LIN_description_file;
LIN_protocol_version = "2.1";
LIN_language_version = "2.1";
LIN_speed = 19.2 kbps;

Nodes {
  Master: EVSE_Master, 1 ms, 0 ms ;
  Slaves: VehicleAC_charger_slave, Cable_Slave ;
}

Signals {
  EvSelectedVersion: 8, 255, VehicleAC_charger_slave, EVSE_Master ;
  EvResponseError: 1, 0, VehicleAC_charger_slave, EVSE_Master ;
  EvStatusVer: 2, 0, VehicleAC_charger_slave, EVSE_Master ;
  EvStatusInit: 2, 0, VehicleAC_charger_slave, EVSE_Master ;
  EvStatusOp: 2, 0, VehicleAC_charger_slave, EVSE_Master ;
  EvAwake: 1, 1, VehicleAC_charger_slave, EVSE_Master ;
  EvVersionPageNumber: 8, 0, VehicleAC_charger_slave, EVSE_Master ;
  EvSupportedVersion1: 8, 2, VehicleAC_charger_slave, EVSE_Master ;
  EvSupportedVersion2: 8, 255, VehicleAC_charger_slave, EVSE_Master ;
  EvSupportedVersion3: 8, 255, VehicleAC_charger_slave, EVSE_Master ;
  EvSupportedVersion4: 8, 255, VehicleAC_charger_slave, EVSE_Master ;
  EvSupportedVersion5: 8, 255, VehicleAC_charger_slave, EVSE_Master ;
  EvRequestedCurrentL1: 8, 255, VehicleAC_charger_slave, EVSE_Master ;
  EvRequestedCurrentL2: 8, 255, VehicleAC_charger_slave, EVSE_Master ;
  EvRequestedCurrentL3: 8, 255, VehicleAC_charger_slave, EVSE_Master ;
  EvRequestedCurrentN: 8, 255, VehicleAC_charger_slave, EVSE_Master ;
  SeSelectedVersion: 8, 255, EVSE_Master, VehicleAC_charger_slave ;
  SeStatusVer: 2, 0, EVSE_Master, VehicleAC_charger_slave ;
  SeStatusInit: 2, 0, EVSE_Master, VehicleAC_charger_slave ;
  SeStatusOp: 2, 0, EVSE_Master, VehicleAC_charger_slave ;
  SeVersionPageNumber: 8, 0, EVSE_Master, VehicleAC_charger_slave ;
  SeSupportedVersion1: 8, 2, EVSE_Master, VehicleAC_charger_slave ;
  SeSupportedVersion2: 8, 255, EVSE_Master, VehicleAC_charger_slave ;
  SeSupportedVersion3: 8, 255, EVSE_Master, VehicleAC_charger_slave ;
  SeSupportedVersion4: 8, 255, EVSE_Master, VehicleAC_charger_slave ;
  SeSupportedVersion5: 8, 255, EVSE_Master, VehicleAC_charger_slave ;
  SeAvailableCurrentL1: 8, 255, EVSE_Master, VehicleAC_charger_slave ;
  SeAvailableCurrentL2: 8, 255, EVSE_Master, VehicleAC_charger_slave ;
  SeAvailableCurrentL3: 8, 255, EVSE_Master, VehicleAC_charger_slave ;
  SeAvailableCurrentN: 8, 255, EVSE_Master, VehicleAC_charger_slave ;
  EvPresentCurrentL1: 8, 255, VehicleAC_charger_slave, EVSE_Master ;
  EvPresentCurrentL2: 8, 255, VehicleAC_charger_slave, EVSE_Master ;
  EvPresentCurrentL3: 8, 255, VehicleAC_charger_slave, EVSE_Master ;
  EvPresentCurrentN: 8, 255, VehicleAC_charger_slave, EVSE_Master ;
  SeNomVoltageL1N: 16, 65535, EVSE_Master, VehicleAC_charger_slave ;
  SeNomVoltageLL: 16, 65535, EVSE_Master, VehicleAC_charger_slave ;
  SeFrequency: 8, 255, EVSE_Master, VehicleAC_charger_slave ;
  SeMaxCurrentL1: 8, 255, EVSE_Master, VehicleAC_charger_slave ;
  SeMaxCurrentL2: 8, 255, EVSE_Master, VehicleAC_charger_slave ;
  SeMaxCurrentL3: 8, 255, EVSE_Master, VehicleAC_charger_slave ;
  SeMaxCurrentN: 8, 255, EVSE_Master, VehicleAC_charger_slave ;
  EvMaxVoltageL1N: 16, 65535, VehicleAC_charger_slave, EVSE_Master ;
  EvMaxVoltageLL: 16, 65535, VehicleAC_charger_slave, EVSE_Master ;
  EvFrequencies: 8, 255, VehicleAC_charger_slave, EVSE_Master ;
  EvMinVoltageL1N: 16, 65535, VehicleAC_charger_slave, EVSE_Master ;
  EvMinVoltageLL: 16, 65535, VehicleAC_charger_slave, EVSE_Master ;
  EvMaxCurrentL1: 8, 255, VehicleAC_charger_slave, EVSE_Master ;
  EvMaxCurrentL2: 8, 255, VehicleAC_charger_slave, EVSE_Master ;
  EvMaxCurrentL3: 8, 255, VehicleAC_charger_slave, EVSE_Master ;
  EvMaxCurrentN: 8, 255, VehicleAC_charger_slave, EVSE_Master ;
  EvMinCurrentL1: 8, 255, VehicleAC_charger_slave, EVSE_Master ;
  EvMinCurrentL2: 8, 255, VehicleAC_charger_slave, EVSE_Master ;
  EvMinCurrentL3: 8, 255, VehicleAC_charger_slave, EVSE_Master ;
  EvInfoEntry1: 8, 255, VehicleAC_charger_slave, EVSE_Master ;
  EvInfoEntry2: 8, 255, VehicleAC_charger_slave, EVSE_Master ;
  EvInfoEntry3: 8, 255, VehicleAC_charger_slave, EVSE_Master ;
  EvInfoEntry4: 8, 255, VehicleAC_charger_slave, EVSE_Master ;
  EvInfoEntry5: 8, 255, VehicleAC_charger_slave, EVSE_Master ;
  EvInfoEntry6: 8, 255, VehicleAC_charger_slave, EVSE_Master ;
  SeInfoEntry1: 8, 255, EVSE_Master, VehicleAC_charger_slave ;
  SeInfoEntry2: 8, 255, EVSE_Master, VehicleAC_charger_slave ;
  SeInfoEntry3: 8, 255, EVSE_Master, VehicleAC_charger_slave ;
  SeInfoEntry4: 8, 255, EVSE_Master, VehicleAC_charger_slave ;
  SeInfoEntry5: 8, 255, EVSE_Master, VehicleAC_charger_slave ;
  SeInfoEntry6: 8, 255, EVSE_Master, VehicleAC_charger_slave ;
  EvInfoPageNumber: 8, 0, VehicleAC_charger_slave, EVSE_Master ;
  SeInfoPageNumber: 8, 0, EVSE_Master, VehicleAC_charger_slave ;
  CaVersion: 8, 0, Cable_Slave, EVSE_Master ;
  CaResponseError: 1, 0, Cable_Slave, EVSE_Master ;
  CaMaxVoltage: 16, 65535, Cable_Slave, EVSE_Master ;
  CaMaxCurrentL1: 8, 255, Cable_Slave, EVSE_Master ;
  CaMaxCurrentL2: 8, 255, Cable_Slave, EVSE_Master ;
  CaMaxCurrentL3: 8, 255, Cable_Slave, EVSE_Master ;
  CaMaxCurrentN: 8, 255, Cable_Slave, EVSE_Master ;
  StErrorPageNumber: 8, 0, EVSE_Master, VehicleAC_charger_slave ;
  StErrorCode1: 8, 255, EVSE_Master, VehicleAC_charger_slave ;
  StErrorCode2: 8, 255, EVSE_Master, VehicleAC_charger_slave ;
  StErrorCode3: 8, 255, EVSE_Master, VehicleAC_charger_slave ;
  StErrorCode4: 8, 255, EVSE_Master, VehicleAC_charger_slave ;
  StErrorCode5: 8, 255, EVSE_Master, VehicleAC_charger_slave ;
  StErrorCode6: 8, 255, EVSE_Master, VehicleAC_charger_slave ;
  EvErrorPageNumber: 8, 0, VehicleAC_charger_slave, EVSE_Master ;
  EvErrorCode1: 8, 255, VehicleAC_charger_slave, EVSE_Master ;
  EvErrorCode2: 8, 255, VehicleAC_charger_slave, EVSE_Master ;
  EvErrorCode3: 8, 255, VehicleAC_charger_slave, EVSE_Master ;
  EvErrorCode4: 8, 255, VehicleAC_charger_slave, EVSE_Master ;
  EvErrorCode5: 8, 255, VehicleAC_charger_slave, EVSE_Master ;
  EvErrorCode6: 8, 255, VehicleAC_charger_slave, EVSE_Master ;
  SeIDPageNumber: 8, 255, EVSE_Master, VehicleAC_charger_slave ;
  SeIDByteA: 8, 255, EVSE_Master, VehicleAC_charger_slave ;
  SeIDByteB: 8, 255, EVSE_Master, VehicleAC_charger_slave ;
  SeIDByteC: 8, 255, EVSE_Master, VehicleAC_charger_slave ;
  SeIDByteD: 8, 255, EVSE_Master, VehicleAC_charger_slave ;
  SeIDByteE: 8, 255, EVSE_Master, VehicleAC_charger_slave ;
  SeIDByteF: 8, 255, EVSE_Master, VehicleAC_charger_slave ;
  SeIDByteG: 8, 255, EVSE_Master, VehicleAC_charger_slave ;
  EvIDPageNumber: 8, 0, VehicleAC_charger_slave, EVSE_Master ;
  EvIDByteA: 8, 0, VehicleAC_charger_slave, EVSE_Master ;
  EvIDByteB: 8, 0, VehicleAC_charger_slave, EVSE_Master ;
  EvIDByteC: 8, 0, VehicleAC_charger_slave, EVSE_Master ;
  EvIDByteD: 8, 0, VehicleAC_charger_slave, EVSE_Master ;
  EvIDByteE: 8, 0, VehicleAC_charger_slave, EVSE_Master ;
  EvIDByteF: 8, 0, VehicleAC_charger_slave, EVSE_Master ;
  EvIDByteG: 8, 0, VehicleAC_charger_slave, EVSE_Master ;
}

Frames {
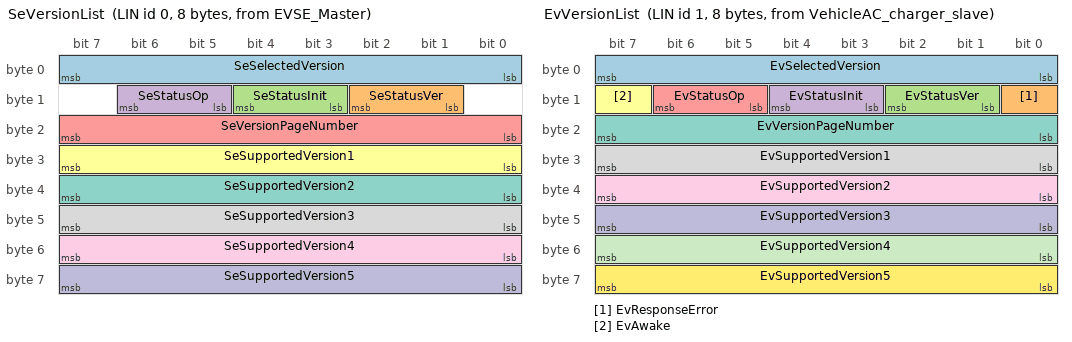
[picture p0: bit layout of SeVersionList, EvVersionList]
  SeVersionList: 0, EVSE_Master, 8 {
    SeSelectedVersion, 0 ;
    SeStatusVer, 9 ;
    SeStatusInit, 11 ;
    SeStatusOp, 13 ;
    SeVersionPageNumber, 16 ;
    SeSupportedVersion1, 24 ;
    SeSupportedVersion2, 32 ;
    SeSupportedVersion3, 40 ;
    SeSupportedVersion4, 48 ;
    SeSupportedVersion5, 56 ;
  }
  EvVersionList: 1, VehicleAC_charger_slave, 8 {
    EvSelectedVersion, 0 ;
    EvResponseError, 8 ;
    EvStatusVer, 9 ;
    EvStatusInit, 11 ;
    EvStatusOp, 13 ;
    EvAwake, 15 ;
    EvVersionPageNumber, 16 ;
    EvSupportedVersion1, 24 ;
    EvSupportedVersion2, 32 ;
    EvSupportedVersion3, 40 ;
    EvSupportedVersion4, 48 ;
    EvSupportedVersion5, 56 ;
  }
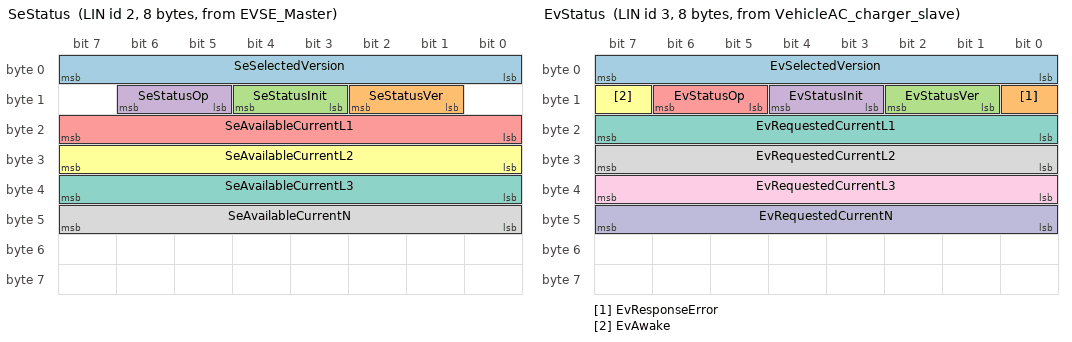
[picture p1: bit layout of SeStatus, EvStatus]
  SeStatus: 2, EVSE_Master, 8 {
    SeSelectedVersion, 0 ;
    SeStatusVer, 9 ;
    SeStatusInit, 11 ;
    SeStatusOp, 13 ;
    SeAvailableCurrentL1, 16 ;
    SeAvailableCurrentL2, 24 ;
    SeAvailableCurrentL3, 32 ;
    SeAvailableCurrentN, 40 ;
  }
  EvStatus: 3, VehicleAC_charger_slave, 8 {
    EvSelectedVersion, 0 ;
    EvResponseError, 8 ;
    EvStatusVer, 9 ;
    EvStatusInit, 11 ;
    EvStatusOp, 13 ;
    EvAwake, 15 ;
    EvRequestedCurrentL1, 16 ;
    EvRequestedCurrentL2, 24 ;
    EvRequestedCurrentL3, 32 ;
    EvRequestedCurrentN, 40 ;
  }
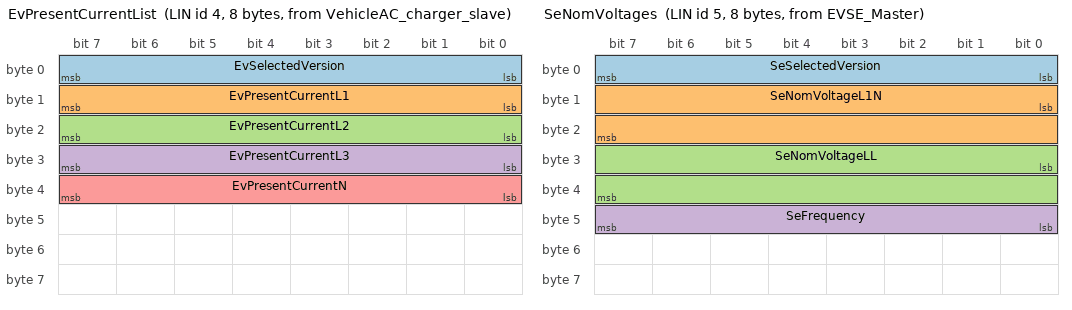
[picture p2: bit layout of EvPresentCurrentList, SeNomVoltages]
  EvPresentCurrentList: 4, VehicleAC_charger_slave, 8 {
    EvSelectedVersion, 0 ;
    EvPresentCurrentL1, 8 ;
    EvPresentCurrentL2, 16 ;
    EvPresentCurrentL3, 24 ;
    EvPresentCurrentN, 32 ;
  }
  SeNomVoltages: 5, EVSE_Master, 8 {
    SeSelectedVersion, 0 ;
    SeNomVoltageL1N, 8 ;
    SeNomVoltageLL, 24 ;
    SeFrequency, 40 ;
  }
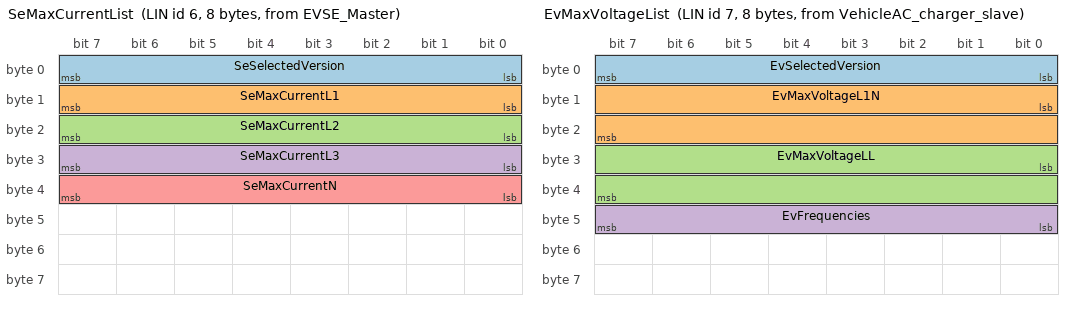
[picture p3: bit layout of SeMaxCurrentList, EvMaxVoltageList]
  SeMaxCurrentList: 6, EVSE_Master, 8 {
    SeSelectedVersion, 0 ;
    SeMaxCurrentL1, 8 ;
    SeMaxCurrentL2, 16 ;
    SeMaxCurrentL3, 24 ;
    SeMaxCurrentN, 32 ;
  }
  EvMaxVoltageList: 7, VehicleAC_charger_slave, 8 {
    EvSelectedVersion, 0 ;
    EvMaxVoltageL1N, 8 ;
    EvMaxVoltageLL, 24 ;
    EvFrequencies, 40 ;
  }
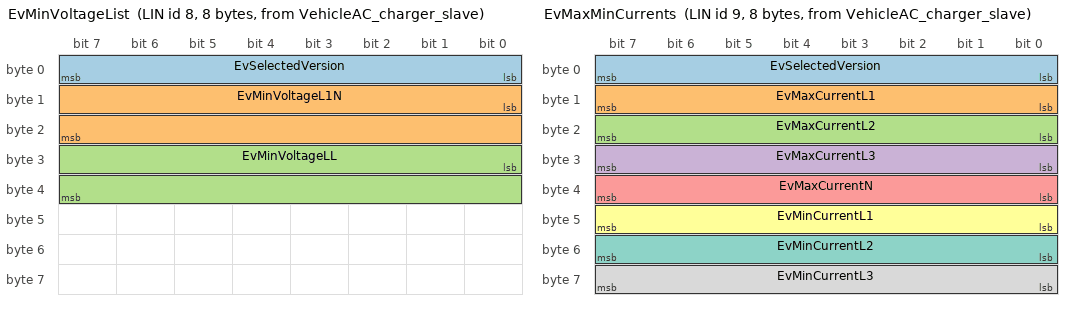
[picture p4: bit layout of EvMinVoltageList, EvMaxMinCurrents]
  EvMinVoltageList: 8, VehicleAC_charger_slave, 8 {
    EvSelectedVersion, 0 ;
    EvMinVoltageL1N, 8 ;
    EvMinVoltageLL, 24 ;
  }
  EvMaxMinCurrents: 9, VehicleAC_charger_slave, 8 {
    EvSelectedVersion, 0 ;
    EvMaxCurrentL1, 8 ;
    EvMaxCurrentL2, 16 ;
    EvMaxCurrentL3, 24 ;
    EvMaxCurrentN, 32 ;
    EvMinCurrentL1, 40 ;
    EvMinCurrentL2, 48 ;
    EvMinCurrentL3, 56 ;
  }
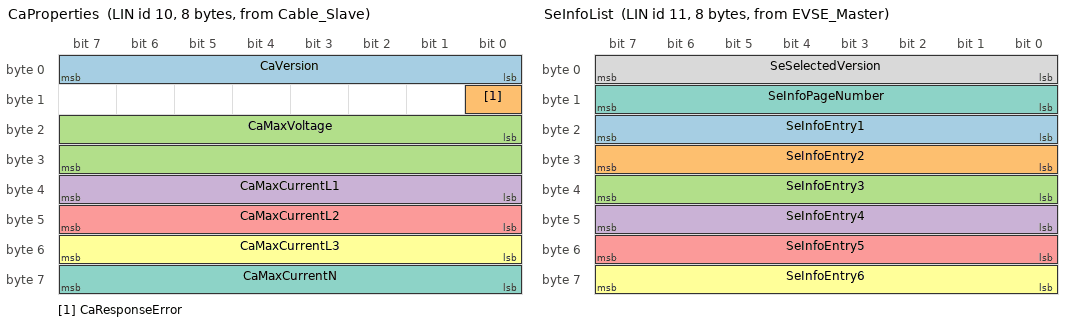
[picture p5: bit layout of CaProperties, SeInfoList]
  CaProperties: 10, Cable_Slave, 8 {
    CaVersion, 0 ;
    CaResponseError, 8 ;
    CaMaxVoltage, 16 ;
    CaMaxCurrentL1, 32 ;
    CaMaxCurrentL2, 40 ;
    CaMaxCurrentL3, 48 ;
    CaMaxCurrentN, 56 ;
  }
  SeInfoList: 11, EVSE_Master, 8 {
    SeInfoEntry1, 16 ;
    SeInfoEntry2, 24 ;
    SeInfoEntry3, 32 ;
    SeInfoEntry4, 40 ;
    SeInfoEntry5, 48 ;
    SeInfoEntry6, 56 ;
    SeInfoPageNumber, 8 ;
    SeSelectedVersion, 0 ;
  }
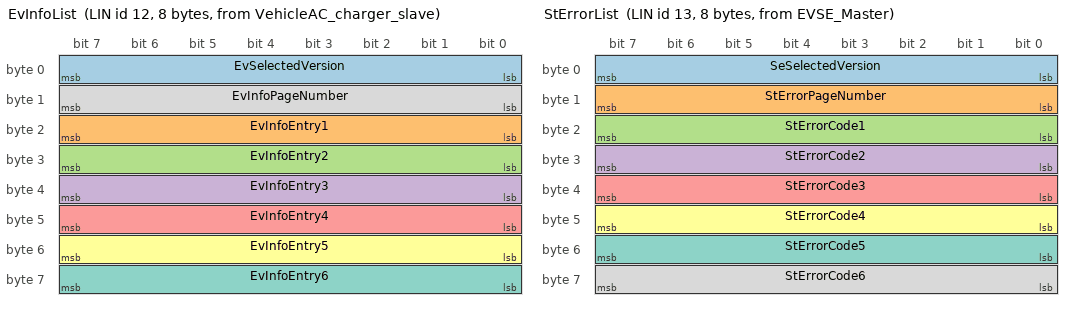
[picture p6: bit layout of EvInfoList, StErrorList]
  EvInfoList: 12, VehicleAC_charger_slave, 8 {
    EvSelectedVersion, 0 ;
    EvInfoEntry1, 16 ;
    EvInfoEntry2, 24 ;
    EvInfoEntry3, 32 ;
    EvInfoEntry4, 40 ;
    EvInfoEntry5, 48 ;
    EvInfoEntry6, 56 ;
    EvInfoPageNumber, 8 ;
  }
  StErrorList: 13, EVSE_Master, 8 {
    SeSelectedVersion, 0 ;
    StErrorPageNumber, 8 ;
    StErrorCode1, 16 ;
    StErrorCode2, 24 ;
    StErrorCode3, 32 ;
    StErrorCode4, 40 ;
    StErrorCode5, 48 ;
    StErrorCode6, 56 ;
  }
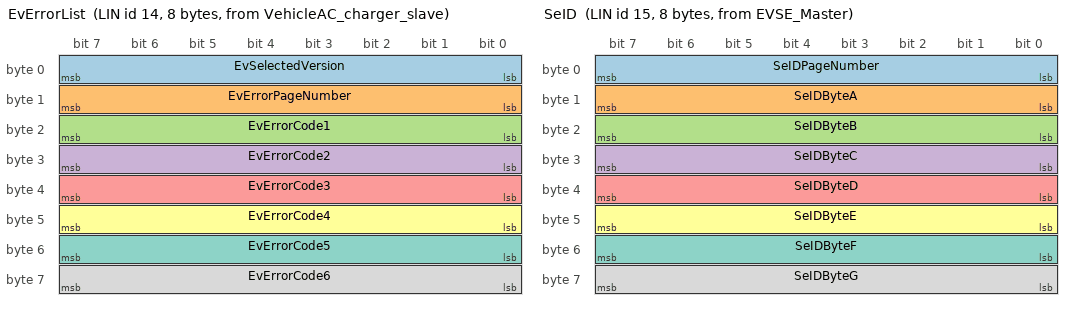
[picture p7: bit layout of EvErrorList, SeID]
  EvErrorList: 14, VehicleAC_charger_slave, 8 {
    EvSelectedVersion, 0 ;
    EvErrorPageNumber, 8 ;
    EvErrorCode1, 16 ;
    EvErrorCode2, 24 ;
    EvErrorCode3, 32 ;
    EvErrorCode4, 40 ;
    EvErrorCode5, 48 ;
    EvErrorCode6, 56 ;
  }
  SeID: 15, EVSE_Master, 8 {
    SeIDPageNumber, 0 ;
    SeIDByteA, 8 ;
    SeIDByteB, 16 ;
    SeIDByteC, 24 ;
    SeIDByteD, 32 ;
    SeIDByteE, 40 ;
    SeIDByteF, 48 ;
    SeIDByteG, 56 ;
  }
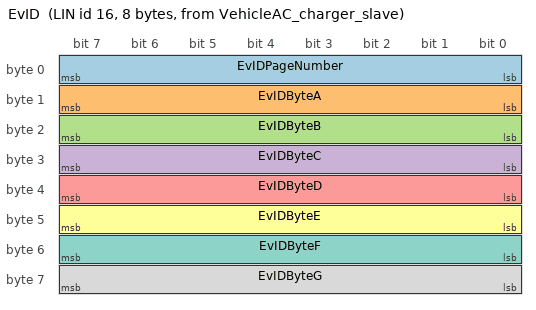
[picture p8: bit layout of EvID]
  EvID: 16, VehicleAC_charger_slave, 8 {
    EvIDPageNumber, 0 ;
    EvIDByteA, 8 ;
    EvIDByteB, 16 ;
    EvIDByteC, 24 ;
    EvIDByteD, 32 ;
    EvIDByteE, 40 ;
    EvIDByteF, 48 ;
    EvIDByteG, 56 ;
  }
}

Node_attributes {
  VehicleAC_charger_slave{
    LIN_protocol = "2.1" ;
    configured_NAD = 0x1 ;
    initial_NAD = 0x1 ;
    product_id = 0x5B, 0x1, 255 ;
    response_error = EvResponseError ;
    P2_min = 50 ms ;
    ST_min = 0 ms ;
    N_As_timeout = 1000 ms ;
    N_Cr_timeout = 1000 ms ;
    configurable_frames {
      SeVersionList ;
      EvVersionList ;
      SeStatus ;
      EvStatus ;
      EvPresentCurrentList ;
      SeNomVoltages ;
      SeMaxCurrentList ;
      EvMaxVoltageList ;
      EvMinVoltageList ;
      EvMaxMinCurrents ;
      EvInfoList ;
      SeInfoList ;
      StErrorList ;
      EvErrorList ;
      SeID;
      EvID;
    }
  }
  Cable_Slave{
    LIN_protocol = "2.1" ;
    configured_NAD = 0x2 ;
    initial_NAD = 0x2 ;
    product_id = 0x5B, 0x1, 255 ;
    response_error = CaResponseError ;
    P2_min = 50 ms ;
    ST_min = 0 ms ;
    N_As_timeout = 1000 ms ;
    N_Cr_timeout = 1000 ms ;
    configurable_frames {
      CaProperties ;
    }
  }
}

Schedule_tables {
 Ver {
    SeVersionList delay 11 ms ;
    EvVersionList delay 11 ms ;
    SeInfoList delay 11 ms ;
    EvInfoList delay 11 ms ;
  }
 Init {
    SeStatus delay 10 ms ;
    EvStatus delay 11 ms ;
    SeNomVoltages delay 10 ms ;
    SeMaxCurrentList delay 11 ms ;
    EvMaxVoltageList delay 10 ms ;
    EvMinVoltageList delay 11 ms ;
    EvMaxMinCurrents delay 10 ms ;
    SeInfoList delay 10 ms ;
    EvInfoList delay 11 ms ;
  }
 Op {
    SeStatus delay 10 ms ;
    EvStatus delay 11 ms ;
    EvPresentCurrentList delay 10 ms ;
    SeInfoList delay 11 ms ;
    EvInfoList delay 10 ms ;
  }
  Op_S1 {
    SeStatus delay 10 ms ;
    EvStatus delay 11 ms ;
    EvPresentCurrentList delay 10 ms ;
    SeInfoList delay 11 ms ;
    EvInfoList delay 10 ms ;
    SeID delay 10 ms;
    EvID delay 10 ms;
  }
}

Signal_encoding_types {
  Awake_Encoding {
    logical_value, 0, "Ev requests to go to sleep" ;
    logical_value, 1, "Ev does not request to go to sleep" ;
  }
  Current_Encoding {
    physical_value, 0, 250, 1, 0, "Amps" ;
    logical_value, 254, "Error" ;
    logical_value, 255, "Not Available" ;
  }
  EvErrorList {
    logical_value, 0, "Unspecified Error" ;
    logical_value, 1, "Reserved" ;
    logical_value, 2, "Reserved" ;
    logical_value, 3, "Reserved" ;
    logical_value, 4, "Reserved" ;
    logical_value, 5, "Reserved" ;
    logical_value, 6, "Reserved" ;
    logical_value, 7, "Reserved" ;
    logical_value, 8, "Reserved" ;
    logical_value, 9, "Reserved" ;
    logical_value, 10, "Reserved" ;
    logical_value, 11, "Reserved" ;
    logical_value, 12, "Reserved" ;
    logical_value, 13, "Reserved" ;
    logical_value, 14, "Reserved" ;
    logical_value, 15, "Reserved" ;
    logical_value, 16, "Reserved" ;
    logical_value, 17, "Reserved" ;
    logical_value, 18, "Reserved" ;
    logical_value, 19, "Reserved" ;
    logical_value, 20, "Reserved" ;
    logical_value, 21, "Reserved" ;
    logical_value, 22, "Reserved" ;
    logical_value, 23, "Reserved" ;
    logical_value, 24, "Reserved" ;
    logical_value, 25, "Reserved" ;
    logical_value, 26, "Reserved" ;
    logical_value, 27, "Reserved" ;
    logical_value, 28, "Reserved" ;
    logical_value, 29, "Reserved" ;
    logical_value, 30, "Reserved" ;
    logical_value, 31, "Reserved" ;
    logical_value, 32, "Reserved" ;
    logical_value, 33, "Reserved" ;
    logical_value, 34, "Reserved" ;
    logical_value, 35, "Reserved" ;
    logical_value, 36, "Reserved" ;
    logical_value, 37, "Reserved" ;
    logical_value, 38, "Reserved" ;
    logical_value, 39, "Reserved" ;
    logical_value, 40, "Reserved" ;
    logical_value, 41, "Reserved" ;
    logical_value, 42, "Reserved" ;
    logical_value, 43, "Reserved" ;
    logical_value, 44, "Reserved" ;
    logical_value, 45, "Reserved" ;
    logical_value, 46, "Reserved" ;
    logical_value, 47, "Reserved" ;
    logical_value, 48, "Reserved" ;
    logical_value, 49, "Reserved" ;
    logical_value, 50, "Reserved" ;
    logical_value, 51, "Reserved" ;
    logical_value, 52, "Reserved" ;
    logical_value, 53, "Reserved" ;
    logical_value, 54, "Reserved" ;
    logical_value, 55, "Reserved" ;
    logical_value, 56, "Reserved" ;
    logical_value, 57, "Reserved" ;
    logical_value, 58, "Reserved" ;
    logical_value, 59, "Reserved" ;
    logical_value, 60, "Reserved" ;
    logical_value, 61, "Reserved" ;
    logical_value, 62, "Reserved" ;
    logical_value, 63, "Reserved" ;
    logical_value, 64, "Reserved" ;
    logical_value, 65, "Reserved" ;
    logical_value, 66, "Reserved" ;
    logical_value, 67, "Reserved" ;
    logical_value, 68, "Reserved" ;
    logical_value, 69, "Reserved" ;
    logical_value, 70, "Reserved" ;
    logical_value, 71, "Reserved" ;
    logical_value, 72, "Reserved" ;
    logical_value, 73, "Reserved" ;
    logical_value, 74, "Reserved" ;
    logical_value, 75, "Reserved" ;
    logical_value, 76, "Reserved" ;
    logical_value, 77, "Reserved" ;
    logical_value, 78, "Reserved" ;
    logical_value, 79, "Reserved" ;
    logical_value, 80, "Reserved" ;
    logical_value, 81, "Reserved" ;
    logical_value, 82, "Reserved" ;
    logical_value, 83, "Reserved" ;
    logical_value, 84, "Reserved" ;
    logical_value, 85, "Reserved" ;
    logical_value, 86, "Reserved" ;
    logical_value, 87, "Reserved" ;
    logical_value, 88, "Reserved" ;
    logical_value, 89, "Reserved" ;
    logical_value, 90, "Reserved" ;
    logical_value, 91, "Reserved" ;
    logical_value, 92, "Reserved" ;
    logical_value, 93, "Reserved" ;
    logical_value, 94, "Reserved" ;
    logical_value, 95, "Reserved" ;
    logical_value, 96, "Reserved" ;
    logical_value, 97, "Reserved" ;
    logical_value, 98, "Reserved" ;
    logical_value, 99, "Reserved" ;
    logical_value, 100, "Reserved" ;
    logical_value, 101, "Reserved" ;
    logical_value, 102, "Reserved" ;
    logical_value, 103, "Reserved" ;
    logical_value, 104, "Reserved" ;
    logical_value, 105, "Reserved" ;
    logical_value, 106, "Reserved" ;
    logical_value, 107, "Reserved" ;
    logical_value, 108, "Reserved" ;
    logical_value, 109, "Reserved" ;
    logical_value, 110, "Reserved" ;
    logical_value, 111, "Reserved" ;
    logical_value, 112, "Reserved" ;
    logical_value, 113, "Reserved" ;
    logical_value, 114, "Reserved" ;
    logical_value, 115, "Reserved" ;
    logical_value, 116, "Reserved" ;
    logical_value, 117, "Reserved" ;
    logical_value, 118, "Reserved" ;
    logical_value, 119, "Reserved" ;
    logical_value, 120, "Reserved" ;
    logical_value, 121, "Reserved" ;
    logical_value, 122, "Reserved" ;
    logical_value, 123, "Reserved" ;
    logical_value, 124, "Reserved" ;
    logical_value, 125, "Reserved" ;
    logical_value, 126, "Reserved" ;
    logical_value, 127, "Reserved" ;
    logical_value, 128, "Reserved" ;
    logical_value, 129, "Reserved" ;
    logical_value, 130, "Reserved" ;
    logical_value, 131, "Reserved" ;
    logical_value, 132, "Reserved" ;
    logical_value, 133, "Reserved" ;
    logical_value, 134, "Reserved" ;
    logical_value, 135, "Reserved" ;
    logical_value, 136, "Reserved" ;
    logical_value, 137, "Reserved" ;
    logical_value, 138, "Reserved" ;
    logical_value, 139, "Reserved" ;
    logical_value, 140, "Reserved" ;
    logical_value, 141, "Reserved" ;
    logical_value, 142, "Reserved" ;
    logical_value, 143, "Reserved" ;
    logical_value, 144, "Reserved" ;
    logical_value, 145, "Reserved" ;
    logical_value, 146, "Reserved" ;
    logical_value, 147, "Reserved" ;
    logical_value, 148, "Reserved" ;
    logical_value, 149, "Reserved" ;
    logical_value, 150, "Reserved" ;
    logical_value, 151, "Reserved" ;
    logical_value, 152, "Reserved" ;
    logical_value, 153, "Reserved" ;
    logical_value, 154, "Reserved" ;
    logical_value, 155, "Reserved" ;
    logical_value, 156, "Reserved" ;
    logical_value, 157, "Reserved" ;
    logical_value, 158, "Reserved" ;
    logical_value, 159, "Reserved" ;
    logical_value, 160, "Reserved" ;
    logical_value, 161, "Reserved" ;
    logical_value, 162, "Reserved" ;
    logical_value, 163, "Reserved" ;
    logical_value, 164, "Reserved" ;
    logical_value, 165, "Reserved" ;
    logical_value, 166, "Reserved" ;
    logical_value, 167, "Reserved" ;
    logical_value, 168, "Reserved" ;
    logical_value, 169, "Reserved" ;
    logical_value, 170, "Reserved" ;
    logical_value, 171, "Reserved" ;
    logical_value, 172, "Reserved" ;
    logical_value, 173, "Reserved" ;
    logical_value, 174, "Reserved" ;
    logical_value, 175, "Reserved" ;
    logical_value, 176, "Reserved" ;
    logical_value, 177, "Reserved" ;
    logical_value, 178, "Reserved" ;
    logical_value, 179, "Reserved" ;
    logical_value, 180, "Reserved" ;
    logical_value, 181, "Reserved" ;
    logical_value, 182, "Reserved" ;
    logical_value, 183, "Reserved" ;
    logical_value, 184, "Reserved" ;
    logical_value, 185, "Reserved" ;
    logical_value, 186, "Reserved" ;
    logical_value, 187, "Reserved" ;
    logical_value, 188, "Reserved" ;
    logical_value, 189, "Reserved" ;
    logical_value, 190, "Reserved" ;
    logical_value, 191, "Reserved" ;
    logical_value, 192, "Reserved" ;
    logical_value, 193, "Reserved" ;
    logical_value, 194, "Reserved" ;
    logical_value, 195, "Reserved" ;
    logical_value, 196, "Reserved" ;
    logical_value, 197, "Reserved" ;
    logical_value, 198, "Reserved" ;
    logical_value, 199, "Reserved" ;
    logical_value, 200, "Reserved" ;
    logical_value, 201, "Reserved" ;
    logical_value, 202, "Reserved" ;
    logical_value, 203, "Reserved" ;
    logical_value, 204, "Reserved" ;
    logical_value, 205, "Reserved" ;
    logical_value, 206, "Reserved" ;
    logical_value, 207, "Reserved" ;
    logical_value, 208, "Reserved" ;
    logical_value, 209, "Reserved" ;
    logical_value, 210, "Reserved" ;
    logical_value, 211, "Reserved" ;
    logical_value, 212, "Reserved" ;
    logical_value, 213, "Reserved" ;
    logical_value, 214, "Reserved" ;
    logical_value, 215, "Reserved" ;
    logical_value, 216, "Reserved" ;
    logical_value, 217, "Reserved" ;
    logical_value, 218, "Reserved" ;
    logical_value, 219, "Reserved" ;
    logical_value, 220, "Reserved" ;
    logical_value, 221, "Reserved" ;
    logical_value, 222, "Reserved" ;
    logical_value, 223, "Reserved" ;
    logical_value, 224, "Manufacturer Specific" ;
    logical_value, 225, "Manufacturer Specific" ;
    logical_value, 226, "Manufacturer Specific" ;
    logical_value, 227, "Manufacturer Specific" ;
    logical_value, 228, "Manufacturer Specific" ;
    logical_value, 229, "Manufacturer Specific" ;
    logical_value, 230, "Manufacturer Specific" ;
    logical_value, 231, "Manufacturer Specific" ;
    logical_value, 232, "Manufacturer Specific" ;
    logical_value, 233, "Manufacturer Specific" ;
    logical_value, 234, "Manufacturer Specific" ;
    logical_value, 235, "Manufacturer Specific" ;
    logical_value, 236, "Manufacturer Specific" ;
    logical_value, 237, "Manufacturer Specific" ;
    logical_value, 238, "Manufacturer Specific" ;
    logical_value, 239, "Manufacturer Specific" ;
    logical_value, 240, "Manufacturer Specific" ;
    logical_value, 241, "Manufacturer Specific" ;
    logical_value, 242, "Manufacturer Specific" ;
    logical_value, 243, "Manufacturer Specific" ;
    logical_value, 244, "Manufacturer Specific" ;
    logical_value, 245, "Manufacturer Specific" ;
    logical_value, 246, "Manufacturer Specific" ;
    logical_value, 247, "Manufacturer Specific" ;
    logical_value, 248, "Manufacturer Specific" ;
    logical_value, 249, "Manufacturer Specific" ;
    logical_value, 250, "Manufacturer Specific" ;
    logical_value, 251, "Manufacturer Specific" ;
    logical_value, 252, "Manufacturer Specific" ;
    logical_value, 253, "Manufacturer Specific" ;
    logical_value, 254, "Manufacturer Specific" ;
    logical_value, 255, "Empty (default)" ;
  }
  EvFrequency_Encoding {
    logical_value, 1, "50Hz" ;
    logical_value, 2, "60Hz" ;
    logical_value, 3, "Utilize 50Hz or 60Hz" ;
    logical_value, 255, "Not Available" ;
  }
  EvInfo {
    logical_value, 0, "Unspecified or other reason" ;
    logical_value, 1, "Charging station is signaling SeStatusOp = not_ready" ;
    logical_value, 2, "Energy management at EV, e.g. battery full or charging to start at a later time" ;
    logical_value, 3, "Charging stopped by user" ;
    logical_value, 4, "Available current too low" ;
    logical_value, 5, "Reserved for Annex D" ;
    logical_value, 6, "Reserved for Annex D" ;
    logical_value, 7, "Reserved for Annex D" ;
    logical_value, 8, "Reserved for Annex D" ;
    logical_value, 9, "Reserved for Annex D" ;
    logical_value, 10, "Reserved for Annex D" ;
    logical_value, 11, "Reserved for Annex D" ;
    logical_value, 12, "Reserved for Annex D" ;
    logical_value, 13, "Reserved for Annex D" ;
    logical_value, 14, "Reserved for Annex D" ;
    logical_value, 15, "Reserved for Annex D" ;
    logical_value, 16, "Reserved for Annex D" ;
    logical_value, 17, "EV determines that Version selection fails" ;
    logical_value, 18, "EV determines that initialization fails" ;
    logical_value, 19, "EV determines to restart the Control Sequence to reselect version" ;
    logical_value, 20, "EV determines to restart the Control Sequence to request a change of bit rate" ;
    logical_value, 21, "EV needs to restart the Control Sequence after an MCU reset" ;
    logical_value, 22, "EV restarts Control Sequence: detected CP Level 0 while prox connected (e.g. SE control power outage)" ;
    logical_value, 23, "EV detects no LIN Headers for longer than TnoLIN" ;
    logical_value, 24, "EV restarts Control Sequence after detecting a recoverable internal fault" ;
    logical_value, 25, "EV will terminate charging, an unrecoverable internal fault was detected" ;
    logical_value, 26, "Maximum available current is too low" ;
    logical_value, 27, "Minimum available voltage is too high" ;
    logical_value, 28, "Frequency does not match" ;
    logical_value, 29, "Charging delayed due to energy management system" ;
    logical_value, 30, "EV isolation fault" ;
    logical_value, 31, "EV is not immediately ready to receive AC voltage" ;
    logical_value, 32, "EV requests AC interruption after reducing current < 1A, sets  Deny_V, opens S2" ;
    logical_value, 33, "EV requests the AC supply voltage to be interrupted by immediately opening S2" ;
    logical_value, 34, "Maximum available voltage is too low" ;
    logical_value, 35, "Reserved" ;
    logical_value, 36, "Reserved" ;
    logical_value, 37, "Reserved" ;
    logical_value, 38, "Reserved" ;
    logical_value, 39, "Reserved" ;
    logical_value, 40, "Reserved" ;
    logical_value, 41, "Reserved" ;
    logical_value, 42, "Reserved" ;
    logical_value, 43, "Reserved" ;
    logical_value, 44, "Reserved" ;
    logical_value, 45, "Reserved" ;
    logical_value, 46, "Reserved" ;
    logical_value, 47, "Reserved" ;
    logical_value, 48, "Reserved" ;
    logical_value, 49, "Reserved" ;
    logical_value, 50, "Reserved" ;
    logical_value, 51, "Reserved" ;
    logical_value, 52, "Reserved" ;
    logical_value, 53, "Reserved" ;
    logical_value, 54, "Reserved" ;
    logical_value, 55, "Reserved" ;
    logical_value, 56, "Reserved" ;
    logical_value, 57, "Reserved" ;
    logical_value, 58, "Reserved" ;
    logical_value, 59, "Reserved" ;
    logical_value, 60, "Reserved" ;
    logical_value, 61, "Reserved" ;
    logical_value, 62, "Reserved" ;
    logical_value, 63, "Reserved" ;
    logical_value, 64, "Reserved" ;
    logical_value, 65, "Reserved" ;
    logical_value, 66, "Reserved" ;
    logical_value, 67, "Reserved" ;
    logical_value, 68, "Reserved" ;
    logical_value, 69, "Reserved" ;
    logical_value, 70, "Reserved" ;
    logical_value, 71, "Reserved" ;
    logical_value, 72, "Reserved" ;
    logical_value, 73, "Reserved" ;
    logical_value, 74, "Reserved" ;
    logical_value, 75, "Reserved" ;
    logical_value, 76, "Reserved" ;
    logical_value, 77, "Reserved" ;
    logical_value, 78, "Reserved" ;
    logical_value, 79, "Reserved" ;
    logical_value, 80, "Reserved" ;
    logical_value, 81, "Reserved" ;
    logical_value, 82, "Reserved" ;
    logical_value, 83, "Reserved" ;
    logical_value, 84, "Reserved" ;
    logical_value, 85, "Reserved" ;
    logical_value, 86, "Reserved" ;
    logical_value, 87, "Reserved" ;
    logical_value, 88, "Reserved" ;
    logical_value, 89, "Reserved" ;
    logical_value, 90, "Reserved" ;
    logical_value, 91, "Reserved" ;
    logical_value, 92, "Reserved" ;
    logical_value, 93, "Reserved" ;
    logical_value, 94, "Reserved" ;
    logical_value, 95, "Reserved" ;
    logical_value, 96, "Reserved" ;
    logical_value, 97, "Reserved" ;
    logical_value, 98, "Reserved" ;
    logical_value, 99, "Reserved" ;
    logical_value, 100, "Reserved" ;
    logical_value, 101, "Reserved" ;
    logical_value, 102, "Reserved" ;
    logical_value, 103, "Reserved" ;
    logical_value, 104, "Reserved" ;
    logical_value, 105, "Reserved" ;
    logical_value, 106, "Reserved" ;
    logical_value, 107, "Reserved" ;
    logical_value, 108, "Reserved" ;
    logical_value, 109, "Reserved" ;
    logical_value, 110, "Reserved" ;
    logical_value, 111, "Reserved" ;
    logical_value, 112, "Reserved" ;
    logical_value, 113, "Reserved" ;
    logical_value, 114, "Reserved" ;
    logical_value, 115, "Reserved" ;
    logical_value, 116, "Reserved" ;
    logical_value, 117, "Reserved" ;
    logical_value, 118, "Reserved" ;
    logical_value, 119, "Reserved" ;
    logical_value, 120, "Reserved" ;
    logical_value, 121, "Reserved" ;
    logical_value, 122, "Reserved" ;
    logical_value, 123, "Reserved" ;
    logical_value, 124, "Reserved" ;
    logical_value, 125, "Reserved" ;
    logical_value, 126, "Reserved" ;
    logical_value, 127, "Reserved" ;
    logical_value, 128, "Reserved" ;
    logical_value, 129, "Reserved" ;
    logical_value, 130, "Reserved" ;
    logical_value, 131, "Reserved" ;
    logical_value, 132, "Reserved" ;
    logical_value, 133, "Reserved" ;
    logical_value, 134, "Reserved" ;
    logical_value, 135, "Reserved" ;
    logical_value, 136, "Reserved" ;
    logical_value, 137, "Reserved" ;
    logical_value, 138, "Reserved" ;
    logical_value, 139, "Reserved" ;
    logical_value, 140, "Reserved" ;
    logical_value, 141, "Reserved" ;
    logical_value, 142, "Reserved" ;
    logical_value, 143, "Reserved" ;
    logical_value, 144, "Reserved" ;
    logical_value, 145, "Reserved" ;
    logical_value, 146, "Reserved" ;
    logical_value, 147, "Reserved" ;
    logical_value, 148, "Reserved" ;
    logical_value, 149, "Reserved" ;
    logical_value, 150, "Reserved" ;
    logical_value, 151, "Reserved" ;
    logical_value, 152, "Reserved" ;
    logical_value, 153, "Reserved" ;
    logical_value, 154, "Reserved" ;
    logical_value, 155, "Reserved" ;
    logical_value, 156, "Reserved" ;
    logical_value, 157, "Reserved" ;
    logical_value, 158, "Reserved" ;
    logical_value, 159, "Reserved" ;
    logical_value, 160, "Reserved" ;
    logical_value, 161, "Reserved" ;
    logical_value, 162, "Reserved" ;
    logical_value, 163, "Reserved" ;
    logical_value, 164, "Reserved" ;
    logical_value, 165, "Reserved" ;
    logical_value, 166, "Reserved" ;
    logical_value, 167, "Reserved" ;
    logical_value, 168, "Reserved" ;
    logical_value, 169, "Reserved" ;
    logical_value, 170, "Reserved" ;
    logical_value, 171, "Reserved" ;
    logical_value, 172, "Reserved" ;
    logical_value, 173, "Reserved" ;
    logical_value, 174, "Reserved" ;
    logical_value, 175, "Reserved" ;
    logical_value, 176, "Reserved" ;
    logical_value, 177, "Reserved" ;
    logical_value, 178, "Reserved" ;
    logical_value, 179, "Reserved" ;
    logical_value, 180, "Reserved" ;
    logical_value, 181, "Reserved" ;
    logical_value, 182, "Reserved" ;
    logical_value, 183, "Reserved" ;
    logical_value, 184, "Reserved" ;
    logical_value, 185, "Reserved" ;
    logical_value, 186, "Reserved" ;
    logical_value, 187, "Reserved" ;
    logical_value, 188, "Reserved" ;
    logical_value, 189, "Reserved" ;
    logical_value, 190, "Reserved" ;
    logical_value, 191, "Reserved" ;
    logical_value, 192, "Reserved" ;
    logical_value, 193, "Reserved" ;
    logical_value, 194, "Reserved" ;
    logical_value, 195, "Reserved" ;
    logical_value, 196, "Reserved" ;
    logical_value, 197, "Reserved" ;
    logical_value, 198, "Reserved" ;
    logical_value, 199, "Reserved" ;
    logical_value, 200, "Reserved" ;
    logical_value, 201, "Reserved" ;
    logical_value, 202, "Reserved" ;
    logical_value, 203, "Reserved" ;
    logical_value, 204, "Reserved" ;
    logical_value, 205, "Reserved" ;
    logical_value, 206, "Reserved" ;
    logical_value, 207, "Reserved" ;
    logical_value, 208, "Reserved" ;
    logical_value, 209, "Reserved" ;
    logical_value, 210, "Reserved" ;
    logical_value, 211, "Reserved" ;
    logical_value, 212, "Reserved" ;
    logical_value, 213, "Reserved" ;
    logical_value, 214, "Reserved" ;
    logical_value, 215, "Reserved" ;
    logical_value, 216, "Reserved" ;
    logical_value, 217, "Reserved" ;
    logical_value, 218, "Reserved" ;
    logical_value, 219, "Reserved" ;
    logical_value, 220, "Reserved" ;
    logical_value, 221, "Reserved" ;
    logical_value, 222, "Reserved" ;
    logical_value, 223, "Reserved" ;
    logical_value, 224, "Manufacturer specific" ;
    logical_value, 225, "Manufacturer specific" ;
    logical_value, 226, "Manufacturer specific" ;
    logical_value, 227, "Manufacturer specific" ;
    logical_value, 228, "Manufacturer specific" ;
    logical_value, 229, "Manufacturer specific" ;
    logical_value, 230, "Manufacturer specific" ;
    logical_value, 231, "Manufacturer specific" ;
    logical_value, 232, "Manufacturer specific" ;
    logical_value, 233, "Manufacturer specific" ;
    logical_value, 234, "Manufacturer specific" ;
    logical_value, 235, "Manufacturer specific" ;
    logical_value, 236, "Manufacturer specific" ;
    logical_value, 237, "Manufacturer specific" ;
    logical_value, 238, "Manufacturer specific" ;
    logical_value, 239, "Manufacturer specific" ;
    logical_value, 240, "Manufacturer specific" ;
    logical_value, 241, "Manufacturer specific" ;
    logical_value, 242, "Manufacturer specific" ;
    logical_value, 243, "Manufacturer specific" ;
    logical_value, 244, "Manufacturer specific" ;
    logical_value, 245, "Manufacturer specific" ;
    logical_value, 246, "Manufacturer specific" ;
    logical_value, 247, "Manufacturer specific" ;
    logical_value, 248, "Manufacturer specific" ;
    logical_value, 249, "Manufacturer specific" ;
    logical_value, 250, "Manufacturer specific" ;
    logical_value, 251, "Manufacturer specific" ;
    logical_value, 252, "Manufacturer specific" ;
    logical_value, 253, "Manufacturer specific" ;
    logical_value, 254, "Manufacturer specific" ;
    logical_value, 255, "Empty (default)" ;
  }
  EvStatusOp_Encoding {
    logical_value, 0, "Deny_V (Annex D: No Error)" ;
    logical_value, 1, "Permit_V (Annex D: reserved)" ;
    logical_value, 2, "Error in Ev" ;
    logical_value, 3, "Not Available" ;
  }
  ResponseError_Encoding {
    logical_value, 0, "No error, transmission sucessful" ;
    logical_value, 1, "Error in frame response" ;
  }
  SeFrequency {
    logical_value, 1, "50Hz" ;
    logical_value, 2, "60Hz" ;
    logical_value, 255, "Not Available" ;
  }
  SeInfo {
    logical_value, 0, "Unspecified error" ;
    logical_value, 1, "EV reset detected" ;
    logical_value, 2, "EV reports an error" ;
    logical_value, 3, "EV does not open S2 when charging station is not ready to supply power" ;
    logical_value, 4, "EV reports an initialization error" ;
    logical_value, 5, "Charging station has detected incompadible parameters" ;
    logical_value, 6, "Initialization timeout at charging station" ;
    logical_value, 7, "Reserved for Annex D" ;
    logical_value, 8, "Reserved for Annex D" ;
    logical_value, 9, "Reserved for Annex D" ;
    logical_value, 10, "Reserved for Annex D" ;
    logical_value, 11, "Reserved for Annex D" ;
    logical_value, 12, "Reserved for Annex D" ;
    logical_value, 13, "Reserved for Annex D" ;
    logical_value, 14, "Reserved for Annex D" ;
    logical_value, 15, "Reserved for Annex D" ;
    logical_value, 16, "Reserved for Annex D" ;
    logical_value, 17, "SE determines that Version selection fails" ;
    logical_value, 18, "SE determines that initialization fails" ;
    logical_value, 19, "SE determines to restart the Control Sequence to reselect version" ;
    logical_value, 20, "SE determines to restart the Control Sequence to request a change of bit rate" ;
    logical_value, 21, "SE needs to restart the Control Sequence after an MCU reset" ;
    logical_value, 22, "SE needs to restart the Control Sequence after a control power outage" ;
    logical_value, 23, "SE detects no LIN Responses for longer than TnoLIN" ;
    logical_value, 24, "SE needs to restart the Control Sequence after detecting an internal fault" ;
    logical_value, 25, "Charging delayed due to energy management system" ;
    logical_value, 26, "Charging stopped by user, for example the stop button on charging station pressed" ;
    logical_value, 27, "Maximum available current is too low (SeMaxCurrents < EvMinCurrents)" ;
    logical_value, 28, "Minimum available voltage is too high (lowest SeNomVoltage > EvMaxVoltage)" ;
    logical_value, 29, "Frequency does not match" ;
    logical_value, 30, "Initialization timeout at charging station" ;
    logical_value, 31, "Over-temperature in Connector" ;
    logical_value, 32, "Over-temperature internally" ;
    logical_value, 33, "Temperature sensor irrational" ;
    logical_value, 34, "Overcurrent (EV load current is too high)" ;
    logical_value, 35, "Current sensor irrational" ;
    logical_value, 36, "Voltage sensor irrational" ;
    logical_value, 37, "Pilot voltage fault" ;
    logical_value, 38, "Contactor fault" ;
    logical_value, 39, "Input miswired" ;
    logical_value, 40, "Input over voltage" ;
    logical_value, 41, "Input under voltage" ;
    logical_value, 42, "CCID self-test fault" ;
    logical_value, 43, "CCID tripped � retry allowed" ;
    logical_value, 44, "CCID tripped � retry limit exceeded" ;
    logical_value, 45, "Breaker tripped" ;
    logical_value, 46, "Ground monitor circuit fault" ;
    logical_value, 47, "Station configuration error" ;
    logical_value, 48, "Improper grounding or Ground is not present" ;
    logical_value, 49, "Problem with EV communications � Disconnect and restart" ;
    logical_value, 50, "Internal EVSE fault � Call for service" ;
    logical_value, 51, "Maximum available voltage is too low" ;
    logical_value, 52, "Reserved" ;
    logical_value, 53, "Reserved" ;
    logical_value, 54, "Reserved" ;
    logical_value, 55, "Reserved" ;
    logical_value, 56, "Reserved" ;
    logical_value, 57, "Reserved" ;
    logical_value, 58, "Reserved" ;
    logical_value, 59, "Reserved" ;
    logical_value, 60, "Reserved" ;
    logical_value, 61, "Reserved" ;
    logical_value, 62, "Reserved" ;
    logical_value, 63, "Reserved" ;
    logical_value, 64, "Reserved" ;
    logical_value, 65, "Reserved" ;
    logical_value, 66, "Reserved" ;
    logical_value, 67, "Reserved" ;
    logical_value, 68, "Reserved" ;
    logical_value, 69, "Reserved" ;
    logical_value, 70, "Reserved" ;
    logical_value, 71, "Reserved" ;
    logical_value, 72, "Reserved" ;
    logical_value, 73, "Reserved" ;
    logical_value, 74, "Reserved" ;
    logical_value, 75, "Reserved" ;
    logical_value, 76, "Reserved" ;
    logical_value, 77, "Reserved" ;
    logical_value, 78, "Reserved" ;
    logical_value, 79, "Reserved" ;
    logical_value, 80, "Reserved" ;
    logical_value, 81, "Reserved" ;
    logical_value, 82, "Reserved" ;
    logical_value, 83, "Reserved" ;
    logical_value, 84, "Reserved" ;
    logical_value, 85, "Reserved" ;
    logical_value, 86, "Reserved" ;
    logical_value, 87, "Reserved" ;
    logical_value, 88, "Reserved" ;
    logical_value, 89, "Reserved" ;
    logical_value, 90, "Reserved" ;
    logical_value, 91, "Reserved" ;
    logical_value, 92, "Reserved" ;
    logical_value, 93, "Reserved" ;
    logical_value, 94, "Reserved" ;
    logical_value, 95, "Reserved" ;
    logical_value, 96, "Reserved" ;
    logical_value, 97, "Reserved" ;
    logical_value, 98, "Reserved" ;
    logical_value, 99, "Reserved" ;
    logical_value, 100, "Reserved" ;
    logical_value, 101, "Reserved" ;
    logical_value, 102, "Reserved" ;
    logical_value, 103, "Reserved" ;
    logical_value, 104, "Reserved" ;
    logical_value, 105, "Reserved" ;
    logical_value, 106, "Reserved" ;
    logical_value, 107, "Reserved" ;
    logical_value, 108, "Reserved" ;
    logical_value, 109, "Reserved" ;
    logical_value, 110, "Reserved" ;
    logical_value, 111, "Reserved" ;
    logical_value, 112, "Reserved" ;
    logical_value, 113, "Reserved" ;
    logical_value, 114, "Reserved" ;
    logical_value, 115, "Reserved" ;
    logical_value, 116, "Reserved" ;
    logical_value, 117, "Reserved" ;
    logical_value, 118, "Reserved" ;
    logical_value, 119, "Reserved" ;
    logical_value, 120, "Reserved" ;
    logical_value, 121, "Reserved" ;
    logical_value, 122, "Reserved" ;
    logical_value, 123, "Reserved" ;
    logical_value, 124, "Reserved" ;
    logical_value, 125, "Reserved" ;
    logical_value, 126, "Reserved" ;
    logical_value, 127, "Reserved" ;
    logical_value, 128, "Reserved" ;
    logical_value, 129, "Reserved" ;
    logical_value, 130, "Reserved" ;
    logical_value, 131, "Reserved" ;
    logical_value, 132, "Reserved" ;
    logical_value, 133, "Reserved" ;
    logical_value, 134, "Reserved" ;
    logical_value, 135, "Reserved" ;
    logical_value, 136, "Reserved" ;
    logical_value, 137, "Reserved" ;
    logical_value, 138, "Reserved" ;
    logical_value, 139, "Reserved" ;
    logical_value, 140, "Reserved" ;
    logical_value, 141, "Reserved" ;
    logical_value, 142, "Reserved" ;
    logical_value, 143, "Reserved" ;
    logical_value, 144, "Reserved" ;
    logical_value, 145, "Reserved" ;
    logical_value, 146, "Reserved" ;
    logical_value, 147, "Reserved" ;
    logical_value, 148, "Reserved" ;
    logical_value, 149, "Reserved" ;
    logical_value, 150, "Reserved" ;
    logical_value, 151, "Reserved" ;
    logical_value, 152, "Reserved" ;
    logical_value, 153, "Reserved" ;
    logical_value, 154, "Reserved" ;
    logical_value, 155, "Reserved" ;
    logical_value, 156, "Reserved" ;
    logical_value, 157, "Reserved" ;
    logical_value, 158, "Reserved" ;
    logical_value, 159, "Reserved" ;
    logical_value, 160, "Reserved" ;
    logical_value, 161, "Reserved" ;
    logical_value, 162, "Reserved" ;
    logical_value, 163, "Reserved" ;
    logical_value, 164, "Reserved" ;
    logical_value, 165, "Reserved" ;
    logical_value, 166, "Reserved" ;
    logical_value, 167, "Reserved" ;
    logical_value, 168, "Reserved" ;
    logical_value, 169, "Reserved" ;
    logical_value, 170, "Reserved" ;
    logical_value, 171, "Reserved" ;
    logical_value, 172, "Reserved" ;
    logical_value, 173, "Reserved" ;
    logical_value, 174, "Reserved" ;
    logical_value, 175, "Reserved" ;
    logical_value, 176, "Reserved" ;
    logical_value, 177, "Reserved" ;
    logical_value, 178, "Reserved" ;
    logical_value, 179, "Reserved" ;
    logical_value, 180, "Reserved" ;
    logical_value, 181, "Reserved" ;
    logical_value, 182, "Reserved" ;
    logical_value, 183, "Reserved" ;
    logical_value, 184, "Reserved" ;
    logical_value, 185, "Reserved" ;
    logical_value, 186, "Reserved" ;
    logical_value, 187, "Reserved" ;
    logical_value, 188, "Reserved" ;
    logical_value, 189, "Reserved" ;
    logical_value, 190, "Reserved" ;
    logical_value, 191, "Reserved" ;
    logical_value, 192, "Reserved" ;
    logical_value, 193, "Reserved" ;
    logical_value, 194, "Reserved" ;
    logical_value, 195, "Reserved" ;
    logical_value, 196, "Reserved" ;
    logical_value, 197, "Reserved" ;
    logical_value, 198, "Reserved" ;
    logical_value, 199, "Reserved" ;
    logical_value, 200, "Reserved" ;
    logical_value, 201, "Reserved" ;
    logical_value, 202, "Reserved" ;
    logical_value, 203, "Reserved" ;
    logical_value, 204, "Reserved" ;
    logical_value, 205, "Reserved" ;
    logical_value, 206, "Reserved" ;
    logical_value, 207, "Reserved" ;
    logical_value, 208, "Reserved" ;
    logical_value, 209, "Reserved" ;
    logical_value, 210, "Reserved" ;
    logical_value, 211, "Reserved" ;
    logical_value, 212, "Reserved" ;
    logical_value, 213, "Reserved" ;
    logical_value, 214, "Reserved" ;
    logical_value, 215, "Reserved" ;
    logical_value, 216, "Reserved" ;
    logical_value, 217, "Reserved" ;
    logical_value, 218, "Reserved" ;
    logical_value, 219, "Reserved" ;
    logical_value, 220, "Reserved" ;
    logical_value, 221, "Reserved" ;
    logical_value, 222, "Reserved" ;
    logical_value, 223, "Reserved" ;
    logical_value, 224, "Manufacturer Specific" ;
    logical_value, 225, "Manufacturer Specific" ;
    logical_value, 226, "Manufacturer Specific" ;
    logical_value, 227, "Manufacturer Specific" ;
    logical_value, 228, "Manufacturer Specific" ;
    logical_value, 229, "Manufacturer Specific" ;
    logical_value, 230, "Manufacturer Specific" ;
    logical_value, 231, "Manufacturer Specific" ;
    logical_value, 232, "Manufacturer Specific" ;
    logical_value, 233, "Manufacturer Specific" ;
    logical_value, 234, "Manufacturer Specific" ;
    logical_value, 235, "Manufacturer Specific" ;
    logical_value, 236, "Manufacturer Specific" ;
    logical_value, 237, "Manufacturer Specific" ;
    logical_value, 238, "Manufacturer Specific" ;
    logical_value, 239, "Manufacturer Specific" ;
    logical_value, 240, "Manufacturer Specific" ;
    logical_value, 241, "Manufacturer Specific" ;
    logical_value, 242, "Manufacturer Specific" ;
    logical_value, 243, "Manufacturer Specific" ;
    logical_value, 244, "Manufacturer Specific" ;
    logical_value, 245, "Manufacturer Specific" ;
    logical_value, 246, "Manufacturer Specific" ;
    logical_value, 247, "Manufacturer Specific" ;
    logical_value, 248, "Manufacturer Specific" ;
    logical_value, 249, "Manufacturer Specific" ;
    logical_value, 250, "Manufacturer Specific" ;
    logical_value, 251, "Manufacturer Specific" ;
    logical_value, 252, "Manufacturer Specific" ;
    logical_value, 253, "Manufacturer Specific" ;
    logical_value, 254, "Manufacturer Specific" ;
    logical_value, 255, "Empty (default)" ;
  }
  SelectedVersion {
    logical_value, 0, "PWM" ;
    logical_value, 1, "Annex D" ;
    logical_value, 2, "SAE J3068" ;
    logical_value, 3, "Reserved" ;
    logical_value, 254, "error" ;
    logical_value, 255, "Not Available" ;
  }
  StErrorList {
    logical_value, 0, "Unspecified Error" ;
    logical_value, 1, "EV reset detected" ;
    logical_value, 2, "EV reports an error, see EvErrorList" ;
    logical_value, 3, "EV does not open S2 when charging station is not ready to supply power" ;
    logical_value, 4, "EV reports and initialization error, see EvErrorList" ;
    logical_value, 5, "Charging station has detected incompatible parameters" ;
    logical_value, 6, "Initialization tinmeout at charging station" ;
    logical_value, 8, "Reserved" ;
    logical_value, 9, "Reserved" ;
    logical_value, 10, "Reserved" ;
    logical_value, 11, "Reserved" ;
    logical_value, 12, "Reserved" ;
    logical_value, 13, "Reserved" ;
    logical_value, 14, "Reserved" ;
    logical_value, 15, "Reserved" ;
    logical_value, 16, "Reserved" ;
    logical_value, 17, "Reserved" ;
    logical_value, 18, "Reserved" ;
    logical_value, 19, "Reserved" ;
    logical_value, 20, "Reserved" ;
    logical_value, 21, "Reserved" ;
    logical_value, 22, "Reserved" ;
    logical_value, 23, "Reserved" ;
    logical_value, 24, "Reserved" ;
    logical_value, 25, "Reserved" ;
    logical_value, 26, "Reserved" ;
    logical_value, 27, "Reserved" ;
    logical_value, 28, "Reserved" ;
    logical_value, 29, "Reserved" ;
    logical_value, 30, "Reserved" ;
    logical_value, 31, "Reserved" ;
    logical_value, 32, "Reserved" ;
    logical_value, 33, "Reserved" ;
    logical_value, 34, "Reserved" ;
    logical_value, 35, "Reserved" ;
    logical_value, 36, "Reserved" ;
    logical_value, 37, "Reserved" ;
    logical_value, 38, "Reserved" ;
    logical_value, 39, "Reserved" ;
    logical_value, 40, "Reserved" ;
    logical_value, 41, "Reserved" ;
    logical_value, 42, "Reserved" ;
    logical_value, 43, "Reserved" ;
    logical_value, 44, "Reserved" ;
    logical_value, 45, "Reserved" ;
    logical_value, 46, "Reserved" ;
    logical_value, 47, "Reserved" ;
    logical_value, 48, "Reserved" ;
    logical_value, 49, "Reserved" ;
    logical_value, 50, "Reserved" ;
    logical_value, 51, "Reserved" ;
    logical_value, 52, "Reserved" ;
    logical_value, 53, "Reserved" ;
    logical_value, 54, "Reserved" ;
    logical_value, 55, "Reserved" ;
    logical_value, 56, "Reserved" ;
    logical_value, 57, "Reserved" ;
    logical_value, 58, "Reserved" ;
    logical_value, 59, "Reserved" ;
    logical_value, 60, "Reserved" ;
    logical_value, 61, "Reserved" ;
    logical_value, 62, "Reserved" ;
    logical_value, 63, "Reserved" ;
    logical_value, 64, "Reserved" ;
    logical_value, 65, "Reserved" ;
    logical_value, 66, "Reserved" ;
    logical_value, 67, "Reserved" ;
    logical_value, 68, "Reserved" ;
    logical_value, 69, "Reserved" ;
    logical_value, 70, "Reserved" ;
    logical_value, 71, "Reserved" ;
    logical_value, 72, "Reserved" ;
    logical_value, 73, "Reserved" ;
    logical_value, 74, "Reserved" ;
    logical_value, 75, "Reserved" ;
    logical_value, 76, "Reserved" ;
    logical_value, 77, "Reserved" ;
    logical_value, 78, "Reserved" ;
    logical_value, 79, "Reserved" ;
    logical_value, 80, "Reserved" ;
    logical_value, 81, "Reserved" ;
    logical_value, 82, "Reserved" ;
    logical_value, 83, "Reserved" ;
    logical_value, 84, "Reserved" ;
    logical_value, 85, "Reserved" ;
    logical_value, 86, "Reserved" ;
    logical_value, 87, "Reserved" ;
    logical_value, 88, "Reserved" ;
    logical_value, 89, "Reserved" ;
    logical_value, 90, "Reserved" ;
    logical_value, 91, "Reserved" ;
    logical_value, 92, "Reserved" ;
    logical_value, 93, "Reserved" ;
    logical_value, 94, "Reserved" ;
    logical_value, 95, "Reserved" ;
    logical_value, 96, "Reserved" ;
    logical_value, 97, "Reserved" ;
    logical_value, 98, "Reserved" ;
    logical_value, 99, "Reserved" ;
    logical_value, 100, "Reserved" ;
    logical_value, 101, "Reserved" ;
    logical_value, 102, "Reserved" ;
    logical_value, 103, "Reserved" ;
    logical_value, 104, "Reserved" ;
    logical_value, 105, "Reserved" ;
    logical_value, 106, "Reserved" ;
    logical_value, 107, "Reserved" ;
    logical_value, 108, "Reserved" ;
    logical_value, 109, "Reserved" ;
    logical_value, 110, "Reserved" ;
    logical_value, 111, "Reserved" ;
    logical_value, 112, "Reserved" ;
    logical_value, 113, "Reserved" ;
    logical_value, 114, "Reserved" ;
    logical_value, 115, "Reserved" ;
    logical_value, 116, "Reserved" ;
    logical_value, 117, "Reserved" ;
    logical_value, 118, "Reserved" ;
    logical_value, 119, "Reserved" ;
    logical_value, 120, "Reserved" ;
    logical_value, 121, "Reserved" ;
    logical_value, 122, "Reserved" ;
    logical_value, 123, "Reserved" ;
    logical_value, 124, "Reserved" ;
    logical_value, 125, "Reserved" ;
    logical_value, 126, "Reserved" ;
    logical_value, 127, "Reserved" ;
    logical_value, 128, "Reserved" ;
    logical_value, 129, "Reserved" ;
    logical_value, 130, "Reserved" ;
    logical_value, 131, "Reserved" ;
    logical_value, 132, "Reserved" ;
    logical_value, 133, "Reserved" ;
    logical_value, 134, "Reserved" ;
    logical_value, 135, "Reserved" ;
    logical_value, 136, "Reserved" ;
    logical_value, 137, "Reserved" ;
    logical_value, 138, "Reserved" ;
    logical_value, 139, "Reserved" ;
    logical_value, 140, "Reserved" ;
    logical_value, 141, "Reserved" ;
    logical_value, 142, "Reserved" ;
    logical_value, 143, "Reserved" ;
    logical_value, 144, "Reserved" ;
    logical_value, 145, "Reserved" ;
    logical_value, 146, "Reserved" ;
    logical_value, 147, "Reserved" ;
    logical_value, 148, "Reserved" ;
    logical_value, 149, "Reserved" ;
    logical_value, 150, "Reserved" ;
    logical_value, 151, "Reserved" ;
    logical_value, 152, "Reserved" ;
    logical_value, 153, "Reserved" ;
    logical_value, 154, "Reserved" ;
    logical_value, 155, "Reserved" ;
    logical_value, 156, "Reserved" ;
    logical_value, 157, "Reserved" ;
    logical_value, 158, "Reserved" ;
    logical_value, 159, "Reserved" ;
    logical_value, 160, "Reserved" ;
    logical_value, 161, "Reserved" ;
    logical_value, 162, "Reserved" ;
    logical_value, 163, "Reserved" ;
    logical_value, 164, "Reserved" ;
    logical_value, 165, "Reserved" ;
    logical_value, 166, "Reserved" ;
    logical_value, 167, "Reserved" ;
    logical_value, 168, "Reserved" ;
    logical_value, 169, "Reserved" ;
    logical_value, 170, "Reserved" ;
    logical_value, 171, "Reserved" ;
    logical_value, 172, "Reserved" ;
    logical_value, 173, "Reserved" ;
    logical_value, 174, "Reserved" ;
    logical_value, 175, "Reserved" ;
    logical_value, 176, "Reserved" ;
    logical_value, 177, "Reserved" ;
    logical_value, 178, "Reserved" ;
    logical_value, 179, "Reserved" ;
    logical_value, 180, "Reserved" ;
    logical_value, 181, "Reserved" ;
    logical_value, 182, "Reserved" ;
    logical_value, 183, "Reserved" ;
    logical_value, 184, "Reserved" ;
    logical_value, 185, "Reserved" ;
    logical_value, 186, "Reserved" ;
    logical_value, 187, "Reserved" ;
    logical_value, 188, "Reserved" ;
    logical_value, 189, "Reserved" ;
    logical_value, 190, "Reserved" ;
    logical_value, 191, "Reserved" ;
    logical_value, 192, "Reserved" ;
    logical_value, 193, "Reserved" ;
    logical_value, 194, "Reserved" ;
    logical_value, 195, "Reserved" ;
    logical_value, 196, "Reserved" ;
    logical_value, 197, "Reserved" ;
    logical_value, 198, "Reserved" ;
    logical_value, 199, "Reserved" ;
    logical_value, 200, "Reserved" ;
    logical_value, 201, "Reserved" ;
    logical_value, 202, "Reserved" ;
    logical_value, 203, "Reserved" ;
    logical_value, 204, "Reserved" ;
    logical_value, 205, "Reserved" ;
    logical_value, 206, "Reserved" ;
    logical_value, 207, "Reserved" ;
    logical_value, 208, "Reserved" ;
    logical_value, 209, "Reserved" ;
    logical_value, 210, "Reserved" ;
    logical_value, 211, "Reserved" ;
    logical_value, 212, "Reserved" ;
    logical_value, 213, "Reserved" ;
    logical_value, 214, "Reserved" ;
    logical_value, 215, "Reserved" ;
    logical_value, 216, "Reserved" ;
    logical_value, 217, "Reserved" ;
    logical_value, 218, "Reserved" ;
    logical_value, 219, "Reserved" ;
    logical_value, 220, "Reserved" ;
    logical_value, 221, "Reserved" ;
    logical_value, 222, "Reserved" ;
    logical_value, 223, "Reserved" ;
    logical_value, 224, "Manufacturer Specific" ;
    logical_value, 225, "Manufacturer Specific" ;
    logical_value, 226, "Manufacturer Specific" ;
    logical_value, 227, "Manufacturer Specific" ;
    logical_value, 228, "Manufacturer Specific" ;
    logical_value, 229, "Manufacturer Specific" ;
    logical_value, 230, "Manufacturer Specific" ;
    logical_value, 231, "Manufacturer Specific" ;
    logical_value, 232, "Manufacturer Specific" ;
    logical_value, 233, "Manufacturer Specific" ;
    logical_value, 234, "Manufacturer Specific" ;
    logical_value, 235, "Manufacturer Specific" ;
    logical_value, 236, "Manufacturer Specific" ;
    logical_value, 237, "Manufacturer Specific" ;
    logical_value, 238, "Manufacturer Specific" ;
    logical_value, 239, "Manufacturer Specific" ;
    logical_value, 240, "Manufacturer Specific" ;
    logical_value, 241, "Manufacturer Specific" ;
    logical_value, 242, "Manufacturer Specific" ;
    logical_value, 243, "Manufacturer Specific" ;
    logical_value, 244, "Manufacturer Specific" ;
    logical_value, 245, "Manufacturer Specific" ;
    logical_value, 246, "Manufacturer Specific" ;
    logical_value, 247, "Manufacturer Specific" ;
    logical_value, 248, "Manufacturer Specific" ;
    logical_value, 249, "Manufacturer Specific" ;
    logical_value, 250, "Manufacturer Specific" ;
    logical_value, 251, "Manufacturer Specific" ;
    logical_value, 252, "Manufacturer Specific" ;
    logical_value, 253, "Manufacturer Specific" ;
    logical_value, 254, "Manufacturer Specific" ;
    logical_value, 255, "Empty (default)" ;
  }
  StatusInitAndVer {
    logical_value, 0, "Incomplete" ;
    logical_value, 1, "Complete" ;
    logical_value, 2, "error" ;
    logical_value, 3, "not available" ;
  }
  StatusOp {
    logical_value, 0, "Deny_V" ;
    logical_value, 1, "Permit_V" ;
    logical_value, 2, "Error" ;
    logical_value, 3, "NotAvailable" ;
  }
  Voltages_Encoding {
    physical_value, 0, 10000, 0.1, 0, "VAC RMS" ;
    logical_value, 65535, "Not Available" ;
  }
}

Signal_representation {
  Awake_Encoding: EvAwake ;
  Current_Encoding: EvRequestedCurrentL1, EvRequestedCurrentL2, EvRequestedCurrentL3, EvRequestedCurrentN, SeAvailableCurrentL1, SeAvailableCurrentL2, SeAvailableCurrentL3, SeAvailableCurrentN, EvPresentCurrentL1, EvPresentCurrentL2, EvPresentCurrentL3, EvPresentCurrentN, SeMaxCurrentL1, SeMaxCurrentL2, SeMaxCurrentL3, SeMaxCurrentN, EvMaxCurrentL1, EvMaxCurrentL2, EvMaxCurrentL3, EvMaxCurrentN, EvMinCurrentL1, EvMinCurrentL2, EvMinCurrentL3, CaMaxCurrentL1, CaMaxCurrentL2, CaMaxCurrentL3, CaMaxCurrentN ;
  EvErrorList: EvErrorCode1, EvErrorCode2, EvErrorCode3, EvErrorCode4, EvErrorCode5, EvErrorCode6 ;
  EvFrequency_Encoding: EvFrequencies ;
  EvInfo: EvInfoEntry1, EvInfoEntry2, EvInfoEntry3, EvInfoEntry4, EvInfoEntry5, EvInfoEntry6 ;
  EvStatusOp_Encoding: EvStatusOp ;
  ResponseError_Encoding: EvResponseError, CaResponseError ;
  SeFrequency: SeFrequency ;
  SeInfo: SeInfoEntry1, SeInfoEntry2, SeInfoEntry3, SeInfoEntry4, SeInfoEntry5, SeInfoEntry6 ;
  SelectedVersion: EvSelectedVersion, EvSupportedVersion1, EvSupportedVersion2, EvSupportedVersion3, EvSupportedVersion4, EvSupportedVersion5, SeSelectedVersion, SeSupportedVersion1, SeSupportedVersion2, SeSupportedVersion3, SeSupportedVersion4, SeSupportedVersion5, CaVersion ;
  StErrorList: StErrorCode1, StErrorCode2, StErrorCode3, StErrorCode4, StErrorCode5 ;
  StatusInitAndVer: EvStatusVer, EvStatusInit, SeStatusVer, SeStatusInit ;
  StatusOp: SeStatusOp, EvStatusOp ;
  Voltages_Encoding: SeNomVoltageL1N, SeNomVoltageLL, EvMaxVoltageL1N, EvMaxVoltageLL, EvMinVoltageL1N, EvMinVoltageLL, CaMaxVoltage ;
}
